VERSION ""

NS_ :

BS_:

BU_:

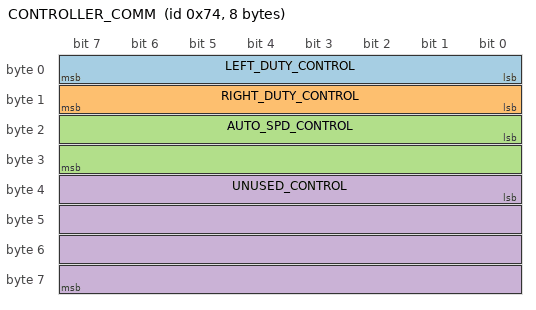
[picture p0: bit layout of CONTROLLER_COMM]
BO_ 116 CONTROLLER_COMM: 8 Vector__XXX
 SG_ LEFT_DUTY_CONTROL: 0|8@1- (1,0) [0|100] "#" Vector__XXX
 SG_ RIGHT_DUTY_CONTROL: 8|8@1- (1,0) [0|100] "#" Vector__XXX
 SG_ AUTO_SPD_CONTROL: 16|16@1- (1,0) [-1000|1000] "#" Vector__XXX
 SG_ UNUSED_CONTROL: 32|32@1- (1,0) [-100|100] "#" Vector__XXX

 BA_DEF_ "BusType" STRING ;
 BA_DEF_DEF_ "BusType" "";
 BA_ "BusType" "CAN";
